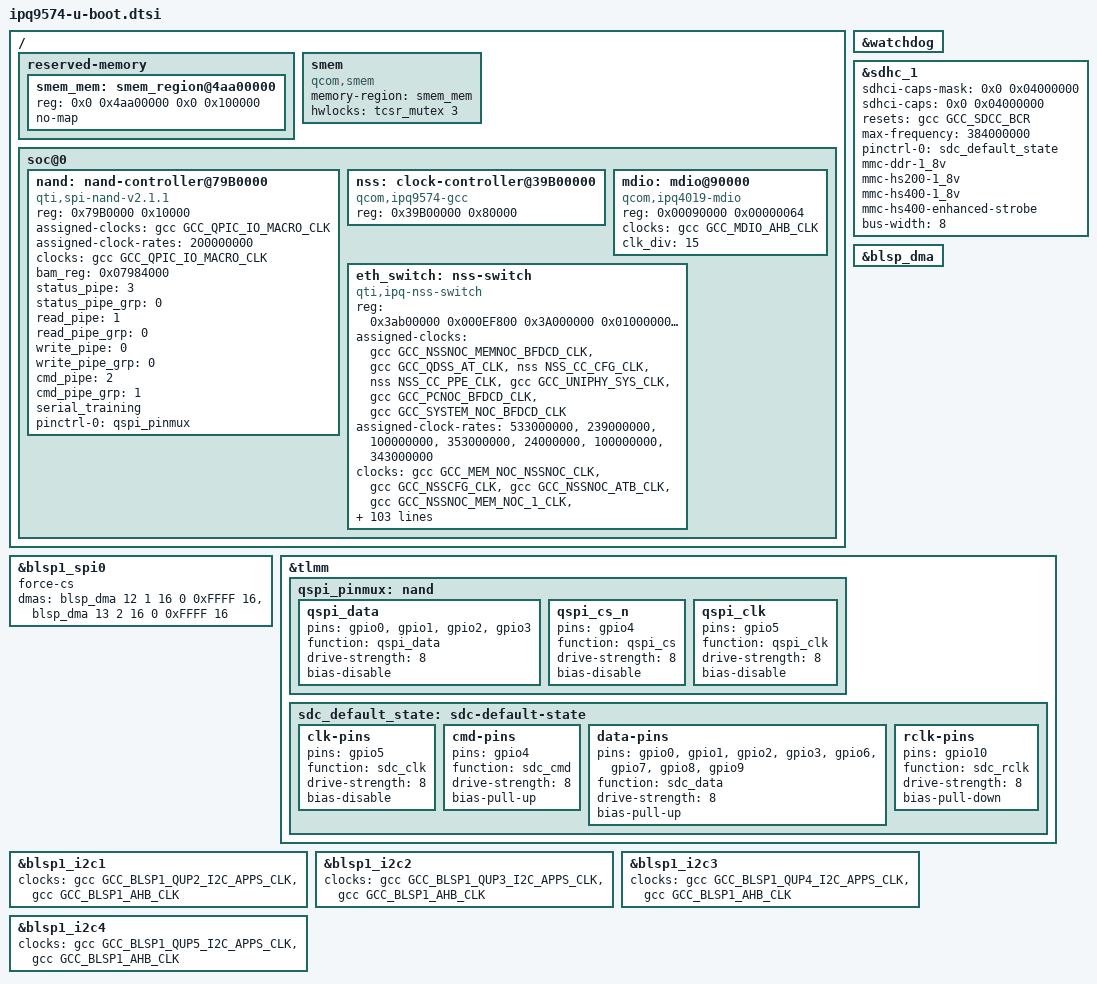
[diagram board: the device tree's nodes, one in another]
// SPDX-License-Identifier: GPL-2.0+
/*
 * Copyright (c) Qualcomm Technologies, Inc. and/or its subsidiaries.
 */

/ {
	reserved-memory {

		/delete-node/ smem;
		smem_mem: smem_region@4aa00000 {
			reg = <0x0 0x4aa00000 0x0 0x100000>;
			no-map;
		};
	};

	smem {
		compatible = "qcom,smem";
		memory-region = <&smem_mem>;
		hwlocks = <&tcsr_mutex 3>;
	};

	soc@0 {
		nand: nand-controller@79B0000 {
			compatible = "qti,spi-nand-v2.1.1";
			#address-cells = <1>;
			#size-cells = <1>;
			reg = <0x79B0000 0x10000>;
			assigned-clocks = <&gcc GCC_QPIC_IO_MACRO_CLK>;
			assigned-clock-rates = <200000000>;
			clock-names = "qpic-io-macro-clk";
			clocks = <&gcc GCC_QPIC_IO_MACRO_CLK>;
			bam_reg = <0x07984000>;
			status_pipe = <3>;
			status_pipe_grp = <0>;
			read_pipe = <1>;
			read_pipe_grp = <0>;
			write_pipe = <0>;
			write_pipe_grp = <0>;
			cmd_pipe = <2>;
			cmd_pipe_grp = <1>;
			serial_training;
			pinctrl-0 = <&qspi_pinmux>;
			pinctrl-names = "default";
			status = "okay";
		};

		nss: clock-controller@39B00000 {
			compatible = "qcom,ipq9574-gcc";
			reg = <0x39B00000 0x80000>;
			#address-cells = <0x1>;
			#size-cells = <0x1>;
			#clock-cells = <1>;
			#reset-cells = <1>;
		};

		/delete-node/ mdio;
		mdio: mdio@90000 {
			#address-cells = <1>;
			#size-cells = <1>;
			compatible = "qcom,ipq4019-mdio";
			reg = <0x00090000 0x00000064>;
			clocks = <&gcc GCC_MDIO_AHB_CLK>;
			clk_div = /bits/ 8 <15>;
			status = "okay";
		};

		eth_switch: nss-switch {
			compatible = "qti,ipq-nss-switch";
			#address-cells = <1>;
			#size-cells = <1>;
			reg = <0x3ab00000 0x000EF800
				0x3A000000 0x01000000
				0x07A00000 0x00010000>;
			reg-names = "edma_hw", "ppe_base", "uniphy_base";
			assigned-clocks = <&gcc GCC_NSSNOC_MEMNOC_BFDCD_CLK>,
					<&gcc GCC_QDSS_AT_CLK>,
					<&nss NSS_CC_CFG_CLK>,
					<&nss NSS_CC_PPE_CLK>,
					<&gcc GCC_UNIPHY_SYS_CLK>,
					<&gcc GCC_PCNOC_BFDCD_CLK>,
					<&gcc GCC_SYSTEM_NOC_BFDCD_CLK>;

			assigned-clock-rates = <533000000>,
						<239000000>,
						<100000000>,
						<353000000>,
						<24000000>,
						<100000000>,
						<343000000>;

			clocks = <&gcc GCC_MEM_NOC_NSSNOC_CLK>,
				<&gcc GCC_NSSCFG_CLK>,
				<&gcc GCC_NSSNOC_ATB_CLK>,
				<&gcc GCC_NSSNOC_MEM_NOC_1_CLK>,
				<&gcc GCC_NSSNOC_MEMNOC_CLK>,
				<&gcc GCC_NSSNOC_QOSGEN_REF_CLK>,
				<&gcc GCC_NSSNOC_TIMEOUT_REF_CLK>,
				<&nss GCC_CMN_12GPLL_AHB_CLK>,
				<&nss GCC_CMN_12GPLL_SYS_CLK>,
				<&gcc GCC_UNIPHY0_SYS_CLK>,
				<&gcc GCC_UNIPHY0_AHB_CLK>,
				<&gcc GCC_UNIPHY1_SYS_CLK>,
				<&gcc GCC_UNIPHY1_AHB_CLK>,
				<&gcc GCC_UNIPHY2_SYS_CLK>,
				<&gcc GCC_UNIPHY2_AHB_CLK>,
				<&gcc GCC_NSSNOC_SNOC_CLK>,
				<&gcc GCC_NSSNOC_SNOC_1_CLK>,
				<&gcc GCC_MEM_NOC_SNOC_AXI_CLK>,
				<&nss NSS_CC_NSS_CSR_CLK>,
				<&nss NSS_CC_NSSNOC_NSS_CSR_CLK>,
				<&nss NSS_CC_PORT1_MAC_CLK>,
				<&nss NSS_CC_PORT2_MAC_CLK>,
				<&nss NSS_CC_PORT3_MAC_CLK>,
				<&nss NSS_CC_PORT4_MAC_CLK>,
				<&nss NSS_CC_PORT5_MAC_CLK>,
				<&nss NSS_CC_PORT6_MAC_CLK>,
				<&nss NSS_CC_PPE_SWITCH_IPE_CLK>,
				<&nss NSS_CC_PPE_SWITCH_CLK>,
				<&nss NSS_CC_PPE_SWITCH_CFG_CLK>,
				<&nss NSS_CC_PPE_EDMA_CLK>,
				<&nss NSS_CC_PPE_EDMA_CFG_CLK>,
				<&nss NSS_CC_CRYPTO_PPE_CLK>,
				<&nss NSS_CC_NSSNOC_PPE_CLK>,
				<&nss NSS_CC_NSSNOC_PPE_CFG_CLK>,
				<&nss NSS_CC_PPE_SWITCH_BTQ_CLK>,
				<&nss NSS_CC_PORT1_RX_CLK>,
				<&nss NSS_CC_PORT1_TX_CLK>,
				<&nss NSS_CC_PORT2_RX_CLK>,
				<&nss NSS_CC_PORT2_TX_CLK>,
				<&nss NSS_CC_PORT3_RX_CLK>,
				<&nss NSS_CC_PORT3_TX_CLK>,
				<&nss NSS_CC_PORT4_RX_CLK>,
				<&nss NSS_CC_PORT4_TX_CLK>,
				<&nss NSS_CC_PORT5_RX_CLK>,
				<&nss NSS_CC_PORT5_TX_CLK>,
				<&nss NSS_CC_PORT6_RX_CLK>,
				<&nss NSS_CC_PORT6_TX_CLK>,
				<&nss NSS_CC_UNIPHY_PORT1_RX_CLK>,
				<&nss NSS_CC_UNIPHY_PORT1_TX_CLK>,
				<&nss NSS_CC_UNIPHY_PORT2_RX_CLK>,
				<&nss NSS_CC_UNIPHY_PORT2_TX_CLK>,
				<&nss NSS_CC_UNIPHY_PORT3_RX_CLK>,
				<&nss NSS_CC_UNIPHY_PORT3_TX_CLK>,
				<&nss NSS_CC_UNIPHY_PORT4_RX_CLK>,
				<&nss NSS_CC_UNIPHY_PORT4_TX_CLK>,
				<&nss NSS_CC_UNIPHY_PORT5_RX_CLK>,
				<&nss NSS_CC_UNIPHY_PORT5_TX_CLK>,
				<&nss NSS_CC_UNIPHY_PORT6_RX_CLK>,
				<&nss NSS_CC_UNIPHY_PORT6_TX_CLK>,
				<&nss UNIPHY0_NSS_RX_CLK>,
				<&nss UNIPHY0_NSS_TX_CLK>,
				<&nss UNIPHY1_NSS_RX_CLK>,
				<&nss UNIPHY1_NSS_TX_CLK>,
				<&nss UNIPHY2_NSS_RX_CLK>,
				<&nss UNIPHY2_NSS_TX_CLK>;

			clock-names = "gcc_mem_noc_nssnoc_clk",
				"gcc_nsscfg_clk",
				"gcc_nssnoc_atb_clk",
				"gcc_nssnoc_mem_noc_1_clk",
				"gcc_nssnoc_memnoc_clk",
				"gcc_nssnoc_qosgen_ref_clk",
				"gcc_nssnoc_timeout_ref_clk",
				"gcc_cmn_12gpll_ahb_clk",
				"gcc_cmn_12gpll_sys_clk",
				"gcc_uniphy0_sys_clk",
				"gcc_uniphy0_ahb_clk",
				"gcc_uniphy1_sys_clk",
				"gcc_uniphy1_ahb_clk",
				"gcc_uniphy2_sys_clk",
				"gcc_uniphy2_ahb_clk",
				"gcc_nssnoc_snoc_clk",
				"gcc_nssnoc_snoc_1_clk",
				"gcc_mem_noc_snoc_axi_clk",
				"nss_cc_nss_csr_clk",
				"nss_cc_nssnoc_nss_csr_clk",
				"nss_cc_port1_mac_clk",
				"nss_cc_port2_mac_clk",
				"nss_cc_port3_mac_clk",
				"nss_cc_port4_mac_clk",
				"nss_cc_port5_mac_clk",
				"nss_cc_port6_mac_clk",
				"nss_cc_ppe_switch_ipe_clk",
				"nss_cc_ppe_switch_clk",
				"nss_cc_ppe_switch_cfg_clk",
				"nss_cc_ppe_edma_clk",
				"nss_cc_ppe_edma_cfg_clk",
				"nss_cc_crypto_ppe_clk",
				"nss_cc_nssnoc_ppe_clk",
				"nss_cc_nssnoc_ppe_cfg_clk",
				"nss_cc_ppe_switch_btq_clk",
				"nss_cc_port1_rx_clk",
				"nss_cc_port1_tx_clk",
				"nss_cc_port2_rx_clk",
				"nss_cc_port2_tx_clk",
				"nss_cc_port3_rx_clk",
				"nss_cc_port3_tx_clk",
				"nss_cc_port4_rx_clk",
				"nss_cc_port4_tx_clk",
				"nss_cc_port5_rx_clk",
				"nss_cc_port5_tx_clk",
				"nss_cc_port6_rx_clk",
				"nss_cc_port6_tx_clk",
				"nss_cc_uniphy_port1_rx_clk",
				"nss_cc_uniphy_port1_tx_clk",
				"nss_cc_uniphy_port2_rx_clk",
				"nss_cc_uniphy_port2_tx_clk",
				"nss_cc_uniphy_port3_rx_clk",
				"nss_cc_uniphy_port3_tx_clk",
				"nss_cc_uniphy_port4_rx_clk",
				"nss_cc_uniphy_port4_tx_clk",
				"nss_cc_uniphy_port5_rx_clk",
				"nss_cc_uniphy_port5_tx_clk",
				"nss_cc_uniphy_port6_rx_clk",
				"nss_cc_uniphy_port6_tx_clk",
				"uniphy0_nss_rx_clk",
				"uniphy0_nss_tx_clk",
				"uniphy1_nss_rx_clk",
				"uniphy1_nss_tx_clk",
				"uniphy2_nss_rx_clk",
				"uniphy2_nss_tx_clk";

			resets = <&gcc GCC_UNIPHY0_SOFT_RESET>,
				<&gcc GCC_UNIPHY1_SOFT_RESET>,
				<&gcc GCC_UNIPHY2_SOFT_RESET>,
				<&gcc GCC_UNIPHY0_XPCS_RESET>,
				<&gcc GCC_UNIPHY1_XPCS_RESET>,
				<&gcc GCC_UNIPHY2_XPCS_RESET>,
				<&nss NSS_CC_UNIPHY_PORT1_TX_RESET>,
				<&nss NSS_CC_UNIPHY_PORT1_RX_RESET>,
				<&nss NSS_CC_UNIPHY_PORT2_TX_RESET>,
				<&nss NSS_CC_UNIPHY_PORT2_RX_RESET>,
				<&nss NSS_CC_UNIPHY_PORT3_TX_RESET>,
				<&nss NSS_CC_UNIPHY_PORT3_RX_RESET>,
				<&nss NSS_CC_UNIPHY_PORT4_TX_RESET>,
				<&nss NSS_CC_UNIPHY_PORT4_RX_RESET>,
				<&nss NSS_CC_UNIPHY_PORT5_TX_RESET>,
				<&nss NSS_CC_UNIPHY_PORT5_RX_RESET>,
				<&nss NSS_CC_UNIPHY_PORT6_TX_RESET>,
				<&nss NSS_CC_UNIPHY_PORT6_RX_RESET>,
				<&nss NSS_CC_PORT1_TX_RESET>,
				<&nss NSS_CC_PORT1_RX_RESET>,
				<&nss NSS_CC_PORT2_TX_RESET>,
				<&nss NSS_CC_PORT2_RX_RESET>,
				<&nss NSS_CC_PORT3_TX_RESET>,
				<&nss NSS_CC_PORT3_RX_RESET>,
				<&nss NSS_CC_PORT4_TX_RESET>,
				<&nss NSS_CC_PORT4_RX_RESET>,
				<&nss NSS_CC_PORT5_TX_RESET>,
				<&nss NSS_CC_PORT5_RX_RESET>,
				<&nss NSS_CC_PORT6_TX_RESET>,
				<&nss NSS_CC_PORT6_RX_RESET>,
				<&nss NSS_CC_PPE_EDMA_RESET>,
				<&nss NSS_CC_PPE_CFG_RESET>,
				<&nss NSS_CC_PORT1_MAC_RESET>,
				<&nss NSS_CC_PORT2_MAC_RESET>,
				<&nss NSS_CC_PORT3_MAC_RESET>,
				<&nss NSS_CC_PORT4_MAC_RESET>,
				<&nss NSS_CC_PORT5_MAC_RESET>,
				<&nss NSS_CC_PORT6_MAC_RESET>;

			reset-names = "uniphy0_srst", "uniphy1_srst",
					"uniphy2_srst", "uniphy0_xrst",
					"uniphy1_xrst", "uniphy2_xrst",
					"uniphy_port1_tx", "uniphy_port1_rx",
					"uniphy_port2_tx", "uniphy_port2_rx",
					"uniphy_port3_tx", "uniphy_port3_rx",
					"uniphy_port4_tx", "uniphy_port4_rx",
					"uniphy_port5_tx", "uniphy_port5_rx",
					"uniphy_port6_tx", "uniphy_port6_rx",
					"nss_cc_port1_tx",
					"nss_cc_port1_rx",
					"nss_cc_port2_tx",
					"nss_cc_port2_rx",
					"nss_cc_port3_tx",
					"nss_cc_port3_rx",
					"nss_cc_port4_tx",
					"nss_cc_port4_rx",
					"nss_cc_port5_tx",
					"nss_cc_port5_rx",
					"nss_cc_port6_tx",
					"nss_cc_port6_rx",
					"nss_cc_ppe_edma",
					"nss_cc_ppe_cfg",
					"nss_cc_port1_mac",
					"nss_cc_port2_mac",
					"nss_cc_port3_mac",
					"nss_cc_port4_mac",
					"nss_cc_port5_mac",
					"nss_cc_port6_mac";
			tdm_offset = <0xc000>;
			tdm_mode = <0>;
			no_tdm_reg = <118>;
			bridge_mode;
			status = "okay";
		};
	};
};

&watchdog {
	status = "okay";
};

&sdhc_1 {
	sdhci-caps-mask = <0x0 0x04000000>;
	sdhci-caps = <0x0 0x04000000>;
	resets = <&gcc GCC_SDCC_BCR>;
	reset-names = "bcr_rst";
	max-frequency = <96000000>;
	pinctrl-0 = <&sdc_default_state>;
	pinctrl-names = "default";
	mmc-ddr-1_8v;
	mmc-hs200-1_8v;
	mmc-hs400-1_8v;
	mmc-hs400-enhanced-strobe;
	max-frequency = <384000000>;
	bus-width = <8>;
	status = "okay";
};

&blsp1_spi0 {
	force-cs;
	dmas = <&blsp_dma 12 1 16 0 0xFFFF 16>,
	       <&blsp_dma 13 2 16 0 0xFFFF 16>;
	status = "okay";
};

&blsp_dma {
	#dma-cells = <6>;
	status = "okay";
};

&tlmm {
	qspi_pinmux: nand {
		qspi_data {
			pins = "gpio0", "gpio1", "gpio2",
				"gpio3";
			function = "qspi_data";
			drive-strength = <8>;
			bias-disable;
		};

		qspi_cs_n {
			pins = "gpio4";
			function = "qspi_cs";
			drive-strength = <8>;
			bias-disable;
		};

		qspi_clk {
			pins = "gpio5";
			function = "qspi_clk";
			drive-strength = <8>;
			bias-disable;
		};
	};

	sdc_default_state: sdc-default-state {
		clk-pins {
			pins = "gpio5";
			function = "sdc_clk";
			drive-strength = <8>;
			bias-disable;
		};

		cmd-pins {
			pins = "gpio4";
			function = "sdc_cmd";
			drive-strength = <8>;
			bias-pull-up;
		};

		data-pins {
			pins = "gpio0", "gpio1", "gpio2",
			       "gpio3", "gpio6", "gpio7",
			       "gpio8", "gpio9";
			function = "sdc_data";
			drive-strength = <8>;
			bias-pull-up;
		};

		rclk-pins {
			pins = "gpio10";
			function = "sdc_rclk";
			drive-strength = <8>;
			bias-pull-down;
		};
	};
};

&blsp1_i2c1 {
	/delete-property/ dmas;
	/delete-property/ clocks;
	/delete-property/ clock-names;
	clocks = <&gcc GCC_BLSP1_QUP2_I2C_APPS_CLK>,
		 <&gcc GCC_BLSP1_AHB_CLK>;
	clock-names = "iface", "core";
};

&blsp1_i2c2 {
	/delete-property/ dmas;
	/delete-property/ clocks;
	/delete-property/ clock-names;
	clocks = <&gcc GCC_BLSP1_QUP3_I2C_APPS_CLK>,
		 <&gcc GCC_BLSP1_AHB_CLK>;
	clock-names = "iface", "core";
};

&blsp1_i2c3 {
	/delete-property/ dmas;
	/delete-property/ clocks;
	/delete-property/ clock-names;
	clocks = <&gcc GCC_BLSP1_QUP4_I2C_APPS_CLK>,
		 <&gcc GCC_BLSP1_AHB_CLK>;
	clock-names = "iface", "core";
};

&blsp1_i2c4 {
	/delete-property/ dmas;
	/delete-property/ clocks;
	/delete-property/ clock-names;
	clocks = <&gcc GCC_BLSP1_QUP5_I2C_APPS_CLK>,
		 <&gcc GCC_BLSP1_AHB_CLK>;
	clock-names = "iface", "core";
};
